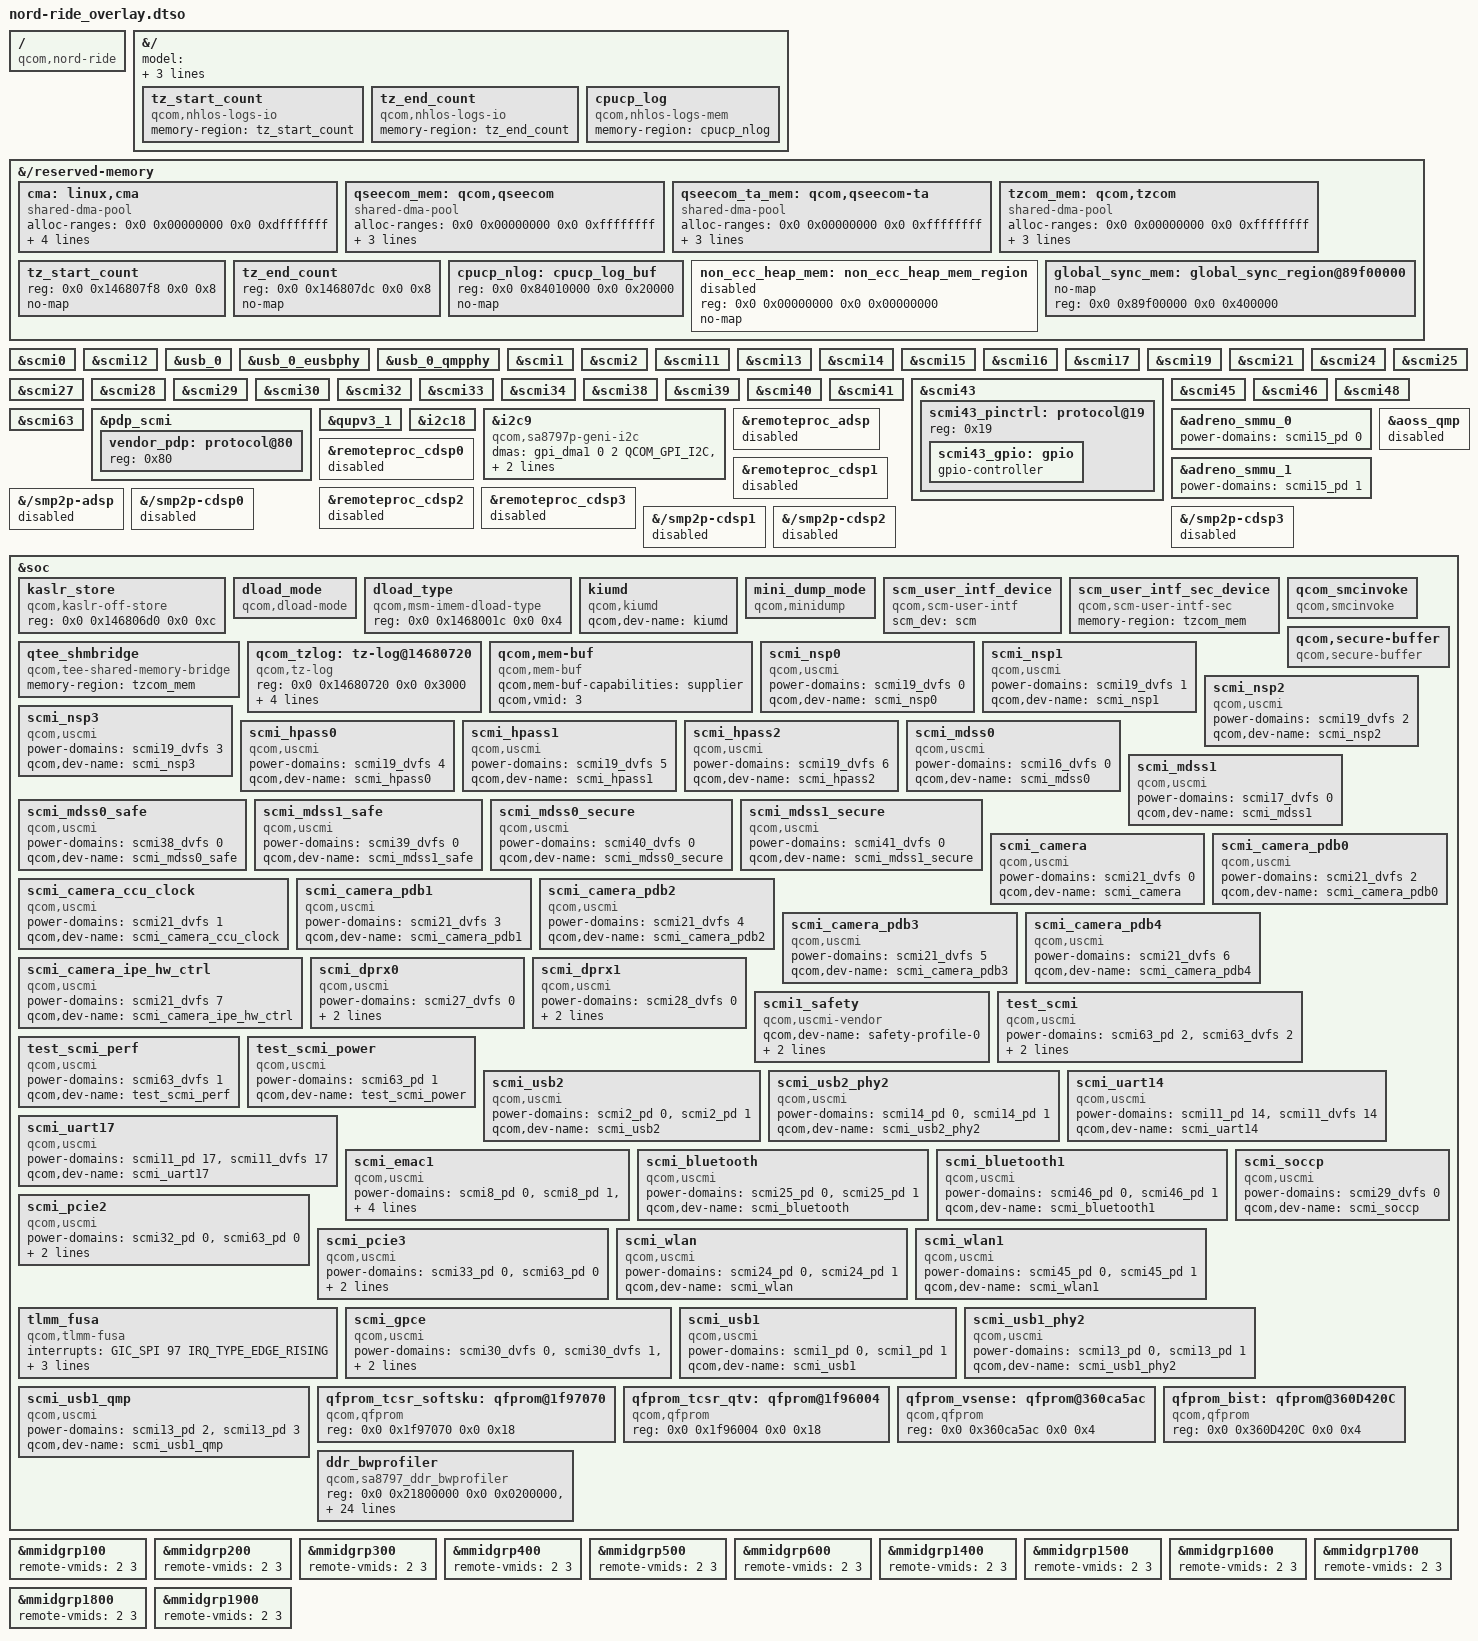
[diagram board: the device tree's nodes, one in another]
// SPDX-License-Identifier: BSD-3-Clause
/*
 * Copyright (c) Qualcomm Technologies, Inc. and/or its subsidiaries.
 */

/dts-v1/;
/plugin/;

#include <dt-bindings/interrupt-controller/arm-gic.h>
#include <dt-bindings/dma/qcom-gpi.h>
#include "oot-dt-bindings/qcom-ipcc-sa8797p.h"
#include "nord-addons.dtsi"
#include "nord-ride-pcie.dtsi"
#include "sa8797p-vfio.dtsi"
#include "sa8797p-vms.dtsi"
#include "sa8797p-dma-heaps.dtsi"
#include "sa8797p-vms-lv.dtsi"
#include "nord-usb.dtsi"

/ {
	compatible = "qcom,nord-ride", "qcom,nord";
};

&{/} {
	model = "Qualcomm Technologies, Inc. NORD v2 QAM RIDE-SX";
	qcom,board-id = <0x01010025 1>;
	qcom,msm-id = <689 0x20000>, <690 0x20000>;
};

&{/} {
	tz_start_count {
		compatible = "qcom,nhlos-logs-io", "qcom,nhlos-logs";
		memory-region = <&tz_start_count>;
	};

	tz_end_count {
		compatible = "qcom,nhlos-logs-io", "qcom,nhlos-logs";
		memory-region = <&tz_end_count>;
	};

	cpucp_log {
		compatible = "qcom,nhlos-logs-mem", "qcom,nhlos-logs";
		memory-region = <&cpucp_nlog>;
	};
};

&{/reserved-memory} {
	cma: linux,cma {
		compatible = "shared-dma-pool";
		alloc-ranges = <0x0 0x00000000 0x0 0xdfffffff>;
		reusable;
		alignment = <0x0 0x400000>;
		size = <0x0 0x2000000>;
		linux,cma-default;
	};
	qseecom_mem: qcom,qseecom {
		compatible = "shared-dma-pool";
		alloc-ranges = <0x0 0x00000000 0x0 0xffffffff>;
		reusable;
		alignment = <0x0 0x400000>;
		size = <0x0 0x1400000>; /* 20M */
	};

	qseecom_ta_mem: qcom,qseecom-ta {
		compatible = "shared-dma-pool";
		alloc-ranges = <0x0 0x00000000 0x0 0xffffffff>;
		reusable;
		alignment = <0x0 0x400000>;
		size = <0x0 0x1000000>; /* 16M */
	};

	tzcom_mem: qcom,tzcom {
		compatible = "shared-dma-pool";
		alloc-ranges = <0x0 0x00000000 0x0 0xffffffff>;
		reusable;
		alignment = <0x0 0x400000>;
		size = <0x0 0x1400000>; /* 20M */
	};

	tz_start_count: tz_start_count {
		reg = <0x0 0x146807f8 0x0 0x8>;
		no-map;
	};

	tz_end_count: tz_end_count {
		reg = <0x0 0x146807dc 0x0 0x8>;
		no-map;
	};

	cpucp_nlog: cpucp_log_buf {
		reg = <0x0 0x84010000 0x0 0x20000>;
		no-map;
	};

	non_ecc_heap_mem: non_ecc_heap_mem_region {
		/* must be overridden by DDR-specific overlay */
		reg = <0x0 0x00000000 0x0 0x00000000>;
		no-map;
		status = "disabled";
	};

	global_sync_mem: global_sync_region@89f00000 {
		no-map;
		reg = <0x0 0x89f00000 0x0 0x400000>;
	};
};


&scmi0 {
	status = "okay";
};

&scmi12 {
	status = "okay";
};

&usb_0 {
	status = "okay";
};

&usb_0_eusbphy {
	status = "okay";
};

&usb_0_qmpphy {
	status = "okay";
};

&scmi1 {
	status = "okay";
};

&scmi2 {
	status = "okay";
};

&scmi11 {
	status = "okay";
};

&scmi13 {
	status = "okay";
};

&scmi14 {
	status = "okay";
};

&scmi15 {
    status = "okay";
};

&scmi16 {
	status = "okay";
};

&scmi17 {
	status = "okay";
};

&scmi19 {
	status = "okay";
};

&scmi21 {
	status = "okay";
};

&scmi24 {
	status = "okay";
};

&scmi25 {
	status = "okay";
};

&scmi27 {
	status = "okay";
};

&scmi28 {
	status = "okay";
};

&scmi29 {
	status = "okay";
};

&scmi30 {
	status = "okay";
};

&scmi32 {
	status = "okay";
};

&scmi33 {
	status = "okay";
};

&scmi34 {
	status = "okay";
};

&scmi38 {
	status = "okay";
};

&scmi39 {
	status = "okay";
};

&scmi40 {
	status = "okay";
};

&scmi41 {
	status = "okay";
};

&scmi43 {
	status = "okay";
};

&scmi45 {
	status = "okay";
};

&scmi46 {
	status = "okay";
};

&scmi48 {
	status = "okay";
};

&scmi63 {
	status = "okay";
};

&scmi43 {
	scmi43_pinctrl: protocol@19 {
		reg = <0x19>;

		scmi43_gpio: gpio {
			gpio-controller;
		};
	};
};

&pdp_scmi {
	vendor_pdp: protocol@80 {
		reg = <0x80>;
		#clock-cells = <1>;
	};
};

&qupv3_1 {
    status = "okay";
};

&i2c18 {
	status = "okay";
};

&i2c9 {
       compatible = "qcom,sa8797p-geni-i2c";
       dmas = <&gpi_dma1 0 2 QCOM_GPI_I2C>,
              <&gpi_dma1 1 2 QCOM_GPI_I2C>;
       dma-names = "tx", "rx";
       power-domains = <&scmi9_pd 9>;
       power-domain-names = "power";
       #address-cells = <1>;
       #size-cells = <0>;
       status = "okay";
};

&adreno_smmu_0 {
    power-domains = <&scmi15_pd 0>;
    power-domain-names = "power";
    status = "okay";
};

&adreno_smmu_1 {
    power-domains = <&scmi15_pd 1>;
    power-domain-names = "power";
    status = "okay";
};

&remoteproc_adsp {
	status = "disabled";
};

&remoteproc_cdsp0 {
	status = "disabled";
};

&remoteproc_cdsp1 {
	status = "disabled";
};

&remoteproc_cdsp2 {
	status = "disabled";
};

&remoteproc_cdsp3 {
	status = "disabled";
};


&{/smp2p-adsp} {
	status = "disabled";
};

&{/smp2p-cdsp0} {
	status = "disabled";
};

&{/smp2p-cdsp1} {
	status = "disabled";
};

&{/smp2p-cdsp2} {
	status = "disabled";
};

&{/smp2p-cdsp3} {
	status = "disabled";
};

&aoss_qmp {
	status = "disabled";
};

&soc {
	kaslr_store {
		compatible = "qcom,kaslr-off-store";
		reg = <0x0 0x146806d0 0x0 0xc>;
	};

	dload_mode {
		compatible = "qcom,dload-mode";
	};

	dload_type {
		compatible = "qcom,msm-imem-dload-type";
		reg = <0x0 0x1468001c 0x0 0x4>;
	};

	kiumd {
		compatible = "qcom,kiumd";
		qcom,dev-name = "kiumd";
		status = "ok";
	};

	mini_dump_mode {
		compatible = "qcom,minidump";
		status = "ok";
	};

	scm_user_intf_device {
		compatible = "qcom,scm-user-intf";
		scm_dev = "scm";
		status = "ok";
	};

	scm_user_intf_sec_device {
		compatible = "qcom,scm-user-intf-sec";
		memory-region = <&tzcom_mem>;
		status = "ok";
	};

	qtee_shmbridge {
		compatible = "qcom,tee-shared-memory-bridge";
		memory-region = <&tzcom_mem>;
	};

	qcom_smcinvoke {
		compatible = "qcom,smcinvoke";
	};

	qcom_tzlog: tz-log@14680720 {
		compatible = "qcom,tz-log";
		reg = <0x0 0x14680720 0x0 0x3000>;
		qcom,hyplog-enabled;
		hyplog-address-offset = <0x410>;
		hyplog-size-offset = <0x414>;
		tmecrashdump-address-offset = <0x87000000>;
	};

	qcom,secure-buffer {
		compatible = "qcom,secure-buffer";
	};

	qcom,mem-buf {
		compatible = "qcom,mem-buf";
		qcom,mem-buf-capabilities = "supplier";
		qcom,vmid = <3>;
	};

	scmi_nsp0 {
		compatible = "qcom,uscmi";

		power-domains = <&scmi19_dvfs 0>;
		power-domain-names = "perf";

		qcom,dev-name = "scmi_nsp0";
	};

	scmi_nsp1 {
		compatible = "qcom,uscmi";

		power-domains = <&scmi19_dvfs 1>;
		power-domain-names = "perf";

		qcom,dev-name = "scmi_nsp1";
	};

	scmi_nsp2 {
		compatible = "qcom,uscmi";

		power-domains = <&scmi19_dvfs 2>;
		power-domain-names = "perf";

		qcom,dev-name = "scmi_nsp2";
	};

	scmi_nsp3 {
		compatible = "qcom,uscmi";

		power-domains = <&scmi19_dvfs 3>;
		power-domain-names = "perf";

		qcom,dev-name = "scmi_nsp3";
	};

	scmi_hpass0 {
		compatible = "qcom,uscmi";

		power-domains = <&scmi19_dvfs 4>;
		power-domain-names = "perf";

		qcom,dev-name = "scmi_hpass0";
	};

	scmi_hpass1 {
		compatible = "qcom,uscmi";

		power-domains = <&scmi19_dvfs 5>;
		power-domain-names = "perf";

		qcom,dev-name = "scmi_hpass1";
	};

	scmi_hpass2 {
		compatible = "qcom,uscmi";

		power-domains = <&scmi19_dvfs 6>;
		power-domain-names = "perf";

		qcom,dev-name = "scmi_hpass2";
	};

	scmi_mdss0 {
		compatible = "qcom,uscmi";

		power-domains = <&scmi16_dvfs 0>;
		power-domain-names = "perf";

		qcom,dev-name = "scmi_mdss0";
	};

	scmi_mdss1 {
		compatible = "qcom,uscmi";

		power-domains = <&scmi17_dvfs 0>;
		power-domain-names = "perf";

		qcom,dev-name = "scmi_mdss1";
	};

	scmi_mdss0_safe {
		compatible = "qcom,uscmi";

		power-domains = <&scmi38_dvfs 0>;
		power-domain-names = "perf";

		qcom,dev-name = "scmi_mdss0_safe";
	};

	scmi_mdss1_safe {
		compatible = "qcom,uscmi";

		power-domains = <&scmi39_dvfs 0>;
		power-domain-names = "perf";

		qcom,dev-name = "scmi_mdss1_safe";
	};

	scmi_mdss0_secure {
		compatible = "qcom,uscmi";

		power-domains = <&scmi40_dvfs 0>;
		power-domain-names = "perf";

		qcom,dev-name = "scmi_mdss0_secure";
	};

	scmi_mdss1_secure {
		compatible = "qcom,uscmi";

		power-domains = <&scmi41_dvfs 0>;
		power-domain-names = "perf";

		qcom,dev-name = "scmi_mdss1_secure";
	};

	scmi_camera {
		compatible = "qcom,uscmi";

		power-domains = <&scmi21_dvfs 0>;
		power-domain-names = "perf_camera_0";

		qcom,dev-name = "scmi_camera";
		};
	scmi_camera_ccu_clock {
		compatible = "qcom,uscmi";

		power-domains = <&scmi21_dvfs 1>;
		power-domain-names = "perf_camera_1";

		qcom,dev-name = "scmi_camera_ccu_clock";
		};

	scmi_camera_pdb0 {
		compatible = "qcom,uscmi";

		power-domains = <&scmi21_dvfs 2>;
		power-domain-names = "perf_camera_config_gpio_0";

		qcom,dev-name = "scmi_camera_pdb0";
        };
	scmi_camera_pdb1 {
		compatible = "qcom,uscmi";

		power-domains = <&scmi21_dvfs 3>;
		power-domain-names = "perf_camera_config_gpio_1";

		qcom,dev-name = "scmi_camera_pdb1";
        };
	scmi_camera_pdb2 {
		compatible = "qcom,uscmi";

		power-domains = <&scmi21_dvfs 4>;
		power-domain-names = "perf_camera_config_gpio_2";

		qcom,dev-name = "scmi_camera_pdb2";
        };
	scmi_camera_pdb3 {
		compatible = "qcom,uscmi";

		power-domains = <&scmi21_dvfs 5>;
		power-domain-names = "perf_camera_config_gpio_3";

		qcom,dev-name = "scmi_camera_pdb3";
        };
	scmi_camera_pdb4 {
		compatible = "qcom,uscmi";

		power-domains = <&scmi21_dvfs 6>;
		power-domain-names = "perf_camera_config_gpio_4";

		qcom,dev-name = "scmi_camera_pdb4";
        };
	scmi_camera_ipe_hw_ctrl {
		compatible = "qcom,uscmi";

		power-domains = <&scmi21_dvfs 7>;
		power-domain-names = "perf_camera_7";

		qcom,dev-name = "scmi_camera_ipe_hw_ctrl";
        };

	scmi_dprx0 {
		compatible = "qcom,uscmi";

		power-domains = <&scmi27_dvfs 0>;
		power-domain-names = "perf";

		resets = <&scmi27_rst 0>;
		reset-names = "dpr0_reset";

		qcom,dev-name = "scmi_dprx0";
	};

	scmi_dprx1 {
		compatible = "qcom,uscmi";

		power-domains = <&scmi28_dvfs 0>;
		power-domain-names = "perf";

		resets = <&scmi28_rst 0>;
		reset-names = "dpr1_reset";

		qcom,dev-name = "scmi_dprx1";
	};

	scmi1_safety {
		qcom,dev-name = "safety-profile-0";
		compatible = "qcom,uscmi-vendor";
		qcom,algo = <0x00 0x73616665>;
		qcom,vendor = <&vendor_pdp>;
	};

	test_scmi {
                compatible = "qcom,uscmi";

                power-domains = <&scmi63_pd 2> , <&scmi63_dvfs 2>;
                power-domain-names = "power", "perf";

                resets = <&scmi63_rst 0>;
                reset-names = "core";

                qcom,dev-name = "test_scmi";
        };

        test_scmi_perf {
                compatible = "qcom,uscmi";

                power-domains = <&scmi63_dvfs 1>;
                power-domain-names = "perf";

                qcom,dev-name = "test_scmi_perf";
        };

        test_scmi_power {
                compatible = "qcom,uscmi";

                power-domains = <&scmi63_pd 1>;

                qcom,dev-name = "test_scmi_power";
        };

	scmi_usb2 {
		compatible = "qcom,uscmi";

		power-domains = <&scmi2_pd 0>, <&scmi2_pd 1>;
		power-domain-names = "usb_transfer", "usb_core";

		qcom,dev-name = "scmi_usb2";
	};

	scmi_usb2_phy2 {
		compatible = "qcom,uscmi";

		power-domains = <&scmi14_pd 0>, <&scmi14_pd 1>;
		power-domain-names = "usb_transfer", "usb_core";

		qcom,dev-name = "scmi_usb2_phy2";
	};

	scmi_uart14 {
		compatible = "qcom,uscmi";

		power-domains = <&scmi11_pd 14>, <&scmi11_dvfs 14>;
		power-domain-names = "power", "perf";

		qcom,dev-name = "scmi_uart14";
	};

	scmi_uart17 {
		compatible = "qcom,uscmi";

		power-domains = <&scmi11_pd 17>, <&scmi11_dvfs 17>;
		power-domain-names = "power", "perf";

		qcom,dev-name = "scmi_uart17";
	};

	scmi_emac1 {
		compatible = "qcom,uscmi";

		power-domains = <&scmi8_pd 0>, <&scmi8_pd 1>, <&scmi8_dvfs 0>, <&scmi8_dvfs 1>;
		power-domain-names = "emac_power", "emac_clock", "emac_perf", "perf_5g_serdes";

		resets = <&scmi8_rst 0>, <&scmi8_rst 1>;
		reset-names = "emac_reset", "serdes_reset";

		qcom,no-suspend;
		qcom,dev-name = "scmi_emac1";
	};

	scmi_bluetooth {
		compatible = "qcom,uscmi";

		power-domains = <&scmi25_pd 0>, <&scmi25_pd 1>;
		power-domain-names = "power_regulator", "power_gpio";
		qcom,dev-name = "scmi_bluetooth";
	};

	scmi_bluetooth1 {
		compatible = "qcom,uscmi";

		power-domains = <&scmi46_pd 0>, <&scmi46_pd 1>;
		power-domain-names = "power_regulator", "power_gpio";
		qcom,dev-name = "scmi_bluetooth1";
	};

	scmi_pcie2 {
		compatible = "qcom,uscmi";

		power-domains = <&scmi32_pd 0>, <&scmi63_pd 0>;
		power-domain-names = "power", "dummy";
		qcom,no-suspend;
		qcom,dev-name = "scmi_pcie2";
	};

	scmi_pcie3 {
		compatible = "qcom,uscmi";

		power-domains = <&scmi33_pd 0>, <&scmi63_pd 0>;
		power-domain-names = "power", "dummy";
		qcom,no-suspend;
		qcom,dev-name = "scmi_pcie3";
	};

	scmi_wlan {
		compatible = "qcom,uscmi";

		power-domains = <&scmi24_pd 0>, <&scmi24_pd 1>;
		power-domain-names = "power_regulator", "power_gpio";

		qcom,dev-name = "scmi_wlan";
	};

	scmi_wlan1 {
		compatible = "qcom,uscmi";

		power-domains = <&scmi45_pd 0>, <&scmi45_pd 1>;
		power-domain-names = "power_regulator", "power_gpio";

		qcom,dev-name = "scmi_wlan1";
	};

	tlmm_fusa {
		compatible = "qcom,tlmm-fusa";
		interrupts = <GIC_SPI 97 IRQ_TYPE_EDGE_RISING>;
		reg = <0x0 0xf1ea000 0x0 0x2>,
		      <0x0 0xf21c000 0x0 0x4>,
		      <0x0 0xf21c008 0x0 0x4>;
		reg-names = "error_status", "ahb_hreset_status", "por_ares_status";
		qcom,por-ares-reset-bit = <6>;
	};

	scmi_soccp {
		compatible = "qcom,uscmi";

		power-domains = <&scmi29_dvfs 0>;
		power-domain-names = "perf";

		qcom,dev-name = "scmi_soccp";
	};

	scmi_gpce {
		compatible = "qcom,uscmi";

		power-domains = <&scmi30_dvfs 0>, <&scmi30_dvfs 1>, <&scmi30_dvfs 2>;
		power-domain-names = "gpce_core0", "gpce_core1", "gpce_core2";

		qcom,dev-name = "scmi_gpce";
	};

	scmi_usb1 {
		compatible = "qcom,uscmi";
		power-domains = <&scmi1_pd 0>, <&scmi1_pd 1>;
		power-domain-names = "usb_transfer", "usb_core";

		qcom,dev-name = "scmi_usb1";
	};

	scmi_usb1_phy2 {
		compatible = "qcom,uscmi";
		power-domains = <&scmi13_pd 0>, <&scmi13_pd 1>;
		power-domain-names = "usb_transfer", "usb_core";

		qcom,dev-name = "scmi_usb1_phy2";
	};

	scmi_usb1_qmp {
		compatible = "qcom,uscmi";
		power-domains = <&scmi13_pd 2>, <&scmi13_pd 3>;
		power-domain-names = "usb_transfer", "usb_core";

		qcom,dev-name = "scmi_usb1_qmp";
	};

	qfprom_tcsr_softsku: qfprom@1f97070 {
		compatible = "qcom,qfprom";
		reg = <0x0 0x1f97070 0x0 0x18>;
		#address-cells = <1>;
		#size-cells = <1>;
	};

	qfprom_tcsr_qtv: qfprom@1f96004 {
		compatible = "qcom,qfprom";
		reg = <0x0 0x1f96004 0x0 0x18>;
		#address-cells = <1>;
		#size-cells = <1>;
	};

	/*
	 * Vsense Calibration Fuse
	 * QFPROM_CORR_CALIBRATION_ROW124_MSB @ 0x360CA5AC
	 * Bits [28:26]:
	 *   0x0       -> Vsense calibration not fused -> voltage monitoring must not be enabled
	 *   0x1 - 0x7 -> Vsense calibration fused     -> voltage monitoring can be enabled
	 */
	qfprom_vsense: qfprom@360ca5ac {
		compatible = "qcom,qfprom";
		reg = <0x0 0x360ca5ac 0x0 0x4>;
		#address-cells = <1>;
		#size-cells = <1>;
	};

	/*
	 * BIST / SMC Fuse
	 * QFPROM_CORR_QC_CONFIG_ROW1_MSB @ 360D420C
	 * Bit 22 (SMC_EN):
	 *   0x0 -> SMC_EN not blown -> BIST capable
	 *   0x1 -> SMC_EN blown     -> BIST not capable
	 */
	qfprom_bist: qfprom@360D420C {
		compatible = "qcom,qfprom";
		reg = <0x0 0x360D420C 0x0 0x4>;
		#address-cells = <1>;
		#size-cells = <1>;
	};
};

&mmidgrp100 {
	remote-vmids = <2 3>;
};

&mmidgrp200 {
	remote-vmids = <2 3>;
};

&mmidgrp300 {
	remote-vmids = <2 3>;
};

&mmidgrp400 {
	remote-vmids = <2 3>;
};

&mmidgrp500 {
	remote-vmids = <2 3>;
};

&mmidgrp600 {
	remote-vmids = <2 3>;
};

&mmidgrp1400 {
	remote-vmids = <2 3>;
};

&mmidgrp1500 {
	remote-vmids = <2 3>;
};

&mmidgrp1600 {
	remote-vmids = <2 3>;
};

&mmidgrp1700 {
	remote-vmids = <2 3>;
};

&mmidgrp1800 {
	remote-vmids = <2 3>;
};

&mmidgrp1900 {
	remote-vmids = <2 3>;
};

&soc {
	ddr_bwprofiler: ddr_bwprofiler {
		compatible = "qcom,sa8797_ddr_bwprofiler";
		reg = <0x0 0x21800000 0x0 0x0200000>,
		    <0x0 0x21A00000 0x0 0x0200000>,
		    <0x0 0x21C00000 0x0 0x0200000>,
		    <0x0 0x21E00000 0x0 0x0200000>,
		    <0x0 0x22800000 0x0 0x0200000>,
		    <0x0 0x22A00000 0x0 0x0200000>,
		    <0x0 0x22C00000 0x0 0x0200000>,
		    <0x0 0x22E00000 0x0 0x0200000>,
		    <0x0 0x23800000 0x0 0x0200000>,
		    <0x0 0x23A00000 0x0 0x0200000>,
		    <0x0 0x23C00000 0x0 0x0200000>,
		    <0x0 0x23E00000 0x0 0x0200000>,
		    <0x0 0x24800000 0x0 0x0200000>,
		    <0x0 0x24A00000 0x0 0x0200000>,
		    <0x0 0x24C00000 0x0 0x0200000>,
		    <0x0 0x24E00000 0x0 0x0200000>,
		    <0x0 0x0232b000 0x0 0x0001000>,
		    <0x0 0x0232c000 0x0 0x0001000>,
		    <0x0 0x0242b000 0x0 0x0001000>,
		    <0x0 0x0242c000 0x0 0x0001000>,
		    <0x0 0x0252b000 0x0 0x0001000>,
		    <0x0 0x0252c000 0x0 0x0001000>,
		    <0x0 0x0272b000 0x0 0x0001000>,
		    <0x0 0x0272c000 0x0 0x0001000>,
		    <0x0 0x01790000 0x0 0x0050000>;
	};
};
